# AC33Mx384A register map
Vendor: ABOV Semiconductor Co., Ltd.; File version: 0.1
ARM 32-bit Cortex-M3 Microcontroller based device.
CPU: CM3 r1p0, little endian, no MPU, no FPU, 3 interrupt priority bits
Registers are 32-bit, read-write, reset 0x0 unless marked. A register's access mark holds for its fields unless they carry their own. Offsets are from the block's base; lines under a group give offsets from that group; [hi:lo] are bit positions; {n}, {i} and the like mark numbered series; 'fields as' and 'values as' point back to an identical list; <NAME> marks a mode.

## Memory map
0x40000000 SCU size 0x100 — SYSTEM CONTROL UNIT
0x40000100 FM size 0x100 — FLASH MEMORY CONTROLLER
0x40000200 WDT size 0x100 — WATCH-DOG TIMER
0x40000400 DC0 size 0x10 — DIRECT MEMORY ACCESS CONTROLLER
0x40000410 DC1 size 0x10
0x40000420 DC2 size 0x10
0x40000430 DC3 size 0x10
0x40000440 DC4 size 0x10
0x40000450 DC5 size 0x10
0x40000460 DC6 size 0x10
0x40000470 DC7 size 0x10
0x40000600 FRT size 0x100 — Free-run Timer
0x40001000 PCA size 0x100 — PORT CONTROL UNIT
0x40001100 PCB size 0x100
0x40001200 PCC size 0x100
0x40001300 PCD size 0x100
0x40001400 PCE size 0x100
0x40001500 PCF size 0x100
0x40001FF0 PORTEN size 0x10 — Port Access Eable
0x40002000 PA size 0x100 — GENERAL PURPOSE I/O
0x40002100 PB size 0x100
0x40002200 PC size 0x100
0x40002300 PD size 0x100
0x40002400 PE size 0x100
0x40002500 PF size 0x100
0x40003000 T0 size 0x20 — 16-BIT TIMER
{0x40003000+0x20*n} T{n} size 0x20 (n=1..9)
0x40003E00 TGECR size 0x10 — Timer Group Encoder Control Register
0x40004000 MP0 size 0x1000 — MOTOR PULSE-WIDTH-MODULATOR
0x40005000 MP1 size 0x1000
0x40008000 U0 size 0x100 — UNIVERSAL ASYNCHRONOUS RECEIVER/TRANSMITTER
0x40008100 U1 size 0x100
0x40008200 U2 size 0x100
0x40008300 U3 size 0x100
0x40009000 SP0 size 0x100 — SERIAL PERIPHERAL INTERFACE
0x40009100 SP1 size 0x100
0x4000A000 IC0 size 0x100 — IIC Interface
0x4000A100 IC1 size 0x100
0x4000B000 AD0 size 0x100 — 12-BIT A/D CONVERTER
0x4000B100 AD1 size 0x100

## Interrupts
0 LVDDETECT (SCU)
1 SCLKFAIL (SCU)
2 XOSCFAIL (SCU)
3 WDT
4 FRT
{n+5} TIMER{n} (T{n}) (n=0..9)
16 GPIOAE (PCA)
17 GPIOAO (PCA)
18 GPIOBE (PCB)
19 GPIOBO (PCB)
20 GPIOCE (PCC)
21 GPIOCO (PCC)
22 GPIODE (PCD)
23 GPIODO (PCD)
24 MPWM0 (MP0)
25 MPWM0PROT (MP0)
26 MPWM0OVV (MP0)
27 MPWM1 (MP1)
28 MPWM1PROT (MP1)
29 MPWM1OVV (MP1)
32 SPI0 (SP0)
33 SPI1 (SP1)
36 IIC0 (IC0)
37 IIC1 (IC1)
38 UART0 (U0)
39 UART1 (U1)
40 UART2 (U2)
41 UART3 (U3)
43 ADC0 (AD0)
44 ADC1 (AD1)
50 GPIOEE (PCE)
51 GPIOEO (PCE)
52 GPIOFE (PCF)
53 GPIOFO (PCF)

## PCA — PORT CONTROL UNIT
Base 0x40001000
Same registers: PCB 0x40001100, PCC 0x40001200, PCD 0x40001300, PCE 0x40001400, PCF 0x40001500
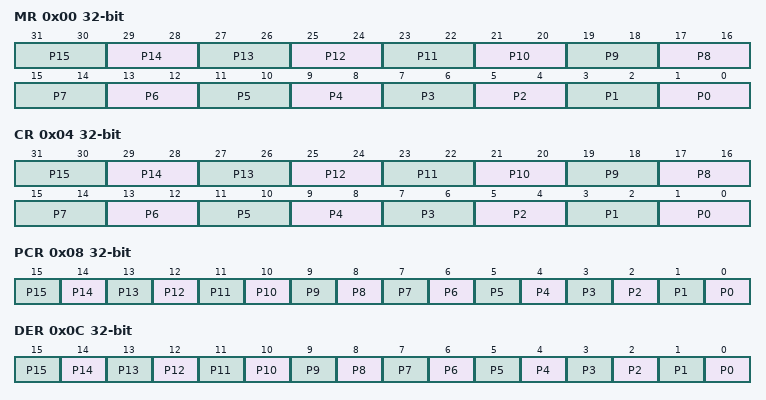
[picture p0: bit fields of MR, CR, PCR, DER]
0x00 MR — PORT n Pin MUX Register
  [2n+1:2n] P{n} (n=0..15) — P{n} MUX SEL
0x04 CR — PORT n Pin Control Register
  [2n+1:2n] P{n} (n=0..15) — P{n} control SEL
0x08 PCR — PORT n Pull-up Resistor Control Register
  [n] P{n} (n=0..15) — P{n} pull-up enable
0x0C DER — PORT n Debounce Enable Register
  [n] P{n} (n=0..15) — P{n} Debounce enable
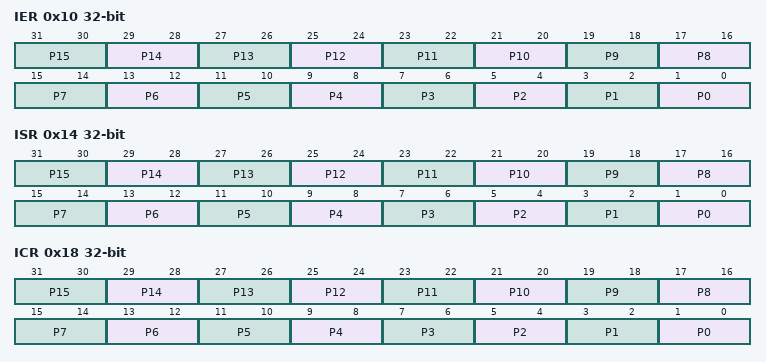
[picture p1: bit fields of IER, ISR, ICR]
0x10 IER — PORT n Interrupt Enable Register
  [2n+1:2n] P{n} (n=0..15) — P{n} interrupt enable
0x14 ISR — PORT n Interrupt Status Register
  [2n+1:2n] P{n} (n=0..15) — P{n} interrupt status
0x18 ICR — PORT n Interrupt Control Register
  [2n+1:2n] P{n} (n=0..15) — P{n} interrupt control

## PORTEN — Port Access Eable
Base 0x40001FF0
0x00 EN (reset mask 0xFFFF) — Port Access Eable 0x15->0x51

## PA — GENERAL PURPOSE I/O
Base 0x40002000
Same registers: PB 0x40002100, PC 0x40002200, PD 0x40002300, PE 0x40002400, PF 0x40002500
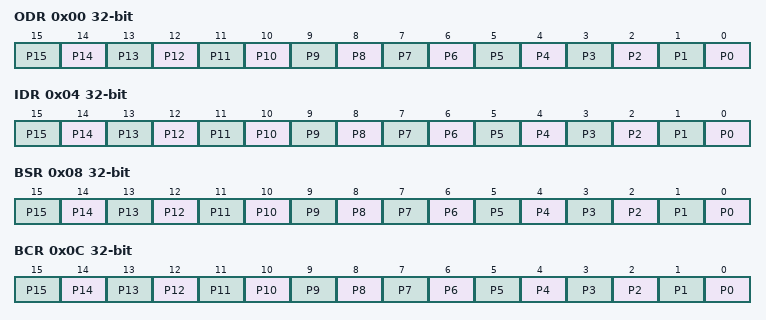
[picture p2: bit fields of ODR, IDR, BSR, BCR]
0x00 ODR — PORT n Output Data Register
  [n] P{n} (n=0..15) — P{n} Output level
0x04 IDR — PORT n Input Data Register
  [n] P{n} (n=0..15) — P{n} Input level
0x08 BSR — PORT n Bit Set Register
  [n] P{n} (n=0..15) — P{n} bit set
0x0C BCR wo — PORT n Bit Clear Register
  [n] P{n} (n=0..15) — P{n} bit clear

## Licence text in the file
THIS SOFTWARE IS PROVIDED "AS IS". NO WARRANTIES, WHETHER EXPRESS, IMPLIED. OR STATUTORY, INCLUDING, BUT NOT LIMITED TO, IMPLIED WARRANTIES OF. MERCHANTABILITY AND FITNESS FOR A PARTICULAR PURPOSE APPLY TO THIS SOFTWARE. ARM SHALL NOT, IN ANY CIRCUMSTANCES, BE LIABLE FOR SPECIAL, INCIDENTAL, OR. CONSEQUENTIAL DAMAGES, FOR ANY REASON WHATSOEVER.
